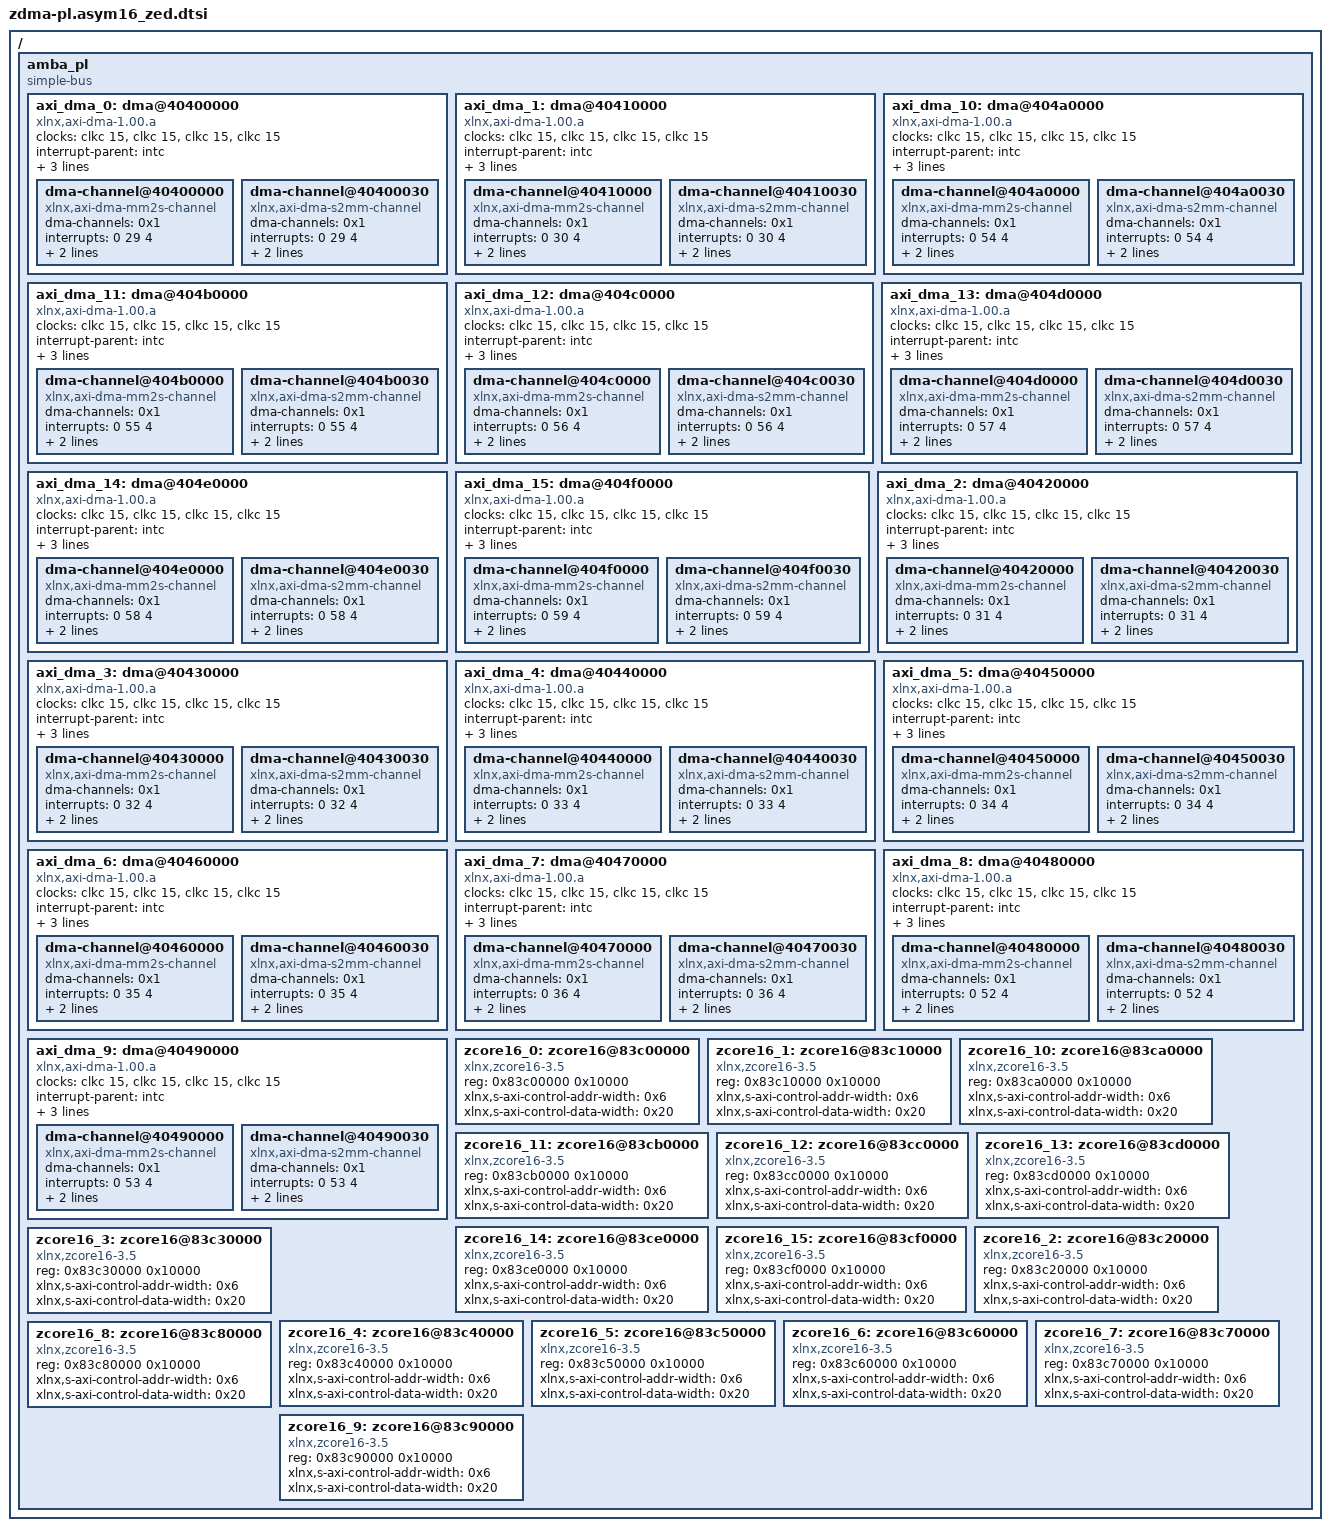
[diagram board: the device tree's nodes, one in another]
/ {
	amba_pl: amba_pl {
		#address-cells = <1>;
		#size-cells = <1>;
		compatible = "simple-bus";
		ranges ;
		axi_dma_0: dma@40400000 {
			#dma-cells = <1>;
			clock-names = "s_axi_lite_aclk", "m_axi_sg_aclk", "m_axi_mm2s_aclk", "m_axi_s2mm_aclk";
			clocks = <&clkc 15>, <&clkc 15>, <&clkc 15>, <&clkc 15>;
			compatible = "xlnx,axi-dma-1.00.a";
			interrupt-parent = <&intc>;
			interrupts = <0 29 4>;
			reg = <0x40400000 0x10000>;
			xlnx,addrwidth = <0x20>;
			dma-channel@40400000 {
				compatible = "xlnx,axi-dma-mm2s-channel";
				dma-channels = <0x1>;
				interrupts = <0 29 4>;
				xlnx,datawidth = <0x10>;
				xlnx,device-id = <0x0>;
			};
			dma-channel@40400030 {
				compatible = "xlnx,axi-dma-s2mm-channel";
				dma-channels = <0x1>;
				interrupts = <0 29 4>;
				xlnx,datawidth = <0x10>;
				xlnx,device-id = <0x0>;
			};
		};
		axi_dma_1: dma@40410000 {
			#dma-cells = <1>;
			clock-names = "s_axi_lite_aclk", "m_axi_sg_aclk", "m_axi_mm2s_aclk", "m_axi_s2mm_aclk";
			clocks = <&clkc 15>, <&clkc 15>, <&clkc 15>, <&clkc 15>;
			compatible = "xlnx,axi-dma-1.00.a";
			interrupt-parent = <&intc>;
			interrupts = <0 30 4>;
			reg = <0x40410000 0x10000>;
			xlnx,addrwidth = <0x20>;
			dma-channel@40410000 {
				compatible = "xlnx,axi-dma-mm2s-channel";
				dma-channels = <0x1>;
				interrupts = <0 30 4>;
				xlnx,datawidth = <0x10>;
				xlnx,device-id = <0x1>;
			};
			dma-channel@40410030 {
				compatible = "xlnx,axi-dma-s2mm-channel";
				dma-channels = <0x1>;
				interrupts = <0 30 4>;
				xlnx,datawidth = <0x10>;
				xlnx,device-id = <0x1>;
			};
		};
		axi_dma_10: dma@404a0000 {
			#dma-cells = <1>;
			clock-names = "s_axi_lite_aclk", "m_axi_sg_aclk", "m_axi_mm2s_aclk", "m_axi_s2mm_aclk";
			clocks = <&clkc 15>, <&clkc 15>, <&clkc 15>, <&clkc 15>;
			compatible = "xlnx,axi-dma-1.00.a";
			interrupt-parent = <&intc>;
			interrupts = <0 54 4>;
			reg = <0x404a0000 0x10000>;
			xlnx,addrwidth = <0x20>;
			dma-channel@404a0000 {
				compatible = "xlnx,axi-dma-mm2s-channel";
				dma-channels = <0x1>;
				interrupts = <0 54 4>;
				xlnx,datawidth = <0x10>;
				xlnx,device-id = <0x2>;
			};
			dma-channel@404a0030 {
				compatible = "xlnx,axi-dma-s2mm-channel";
				dma-channels = <0x1>;
				interrupts = <0 54 4>;
				xlnx,datawidth = <0x10>;
				xlnx,device-id = <0x2>;
			};
		};
		axi_dma_11: dma@404b0000 {
			#dma-cells = <1>;
			clock-names = "s_axi_lite_aclk", "m_axi_sg_aclk", "m_axi_mm2s_aclk", "m_axi_s2mm_aclk";
			clocks = <&clkc 15>, <&clkc 15>, <&clkc 15>, <&clkc 15>;
			compatible = "xlnx,axi-dma-1.00.a";
			interrupt-parent = <&intc>;
			interrupts = <0 55 4>;
			reg = <0x404b0000 0x10000>;
			xlnx,addrwidth = <0x20>;
			dma-channel@404b0000 {
				compatible = "xlnx,axi-dma-mm2s-channel";
				dma-channels = <0x1>;
				interrupts = <0 55 4>;
				xlnx,datawidth = <0x10>;
				xlnx,device-id = <0x3>;
			};
			dma-channel@404b0030 {
				compatible = "xlnx,axi-dma-s2mm-channel";
				dma-channels = <0x1>;
				interrupts = <0 55 4>;
				xlnx,datawidth = <0x10>;
				xlnx,device-id = <0x3>;
			};
		};
		axi_dma_12: dma@404c0000 {
			#dma-cells = <1>;
			clock-names = "s_axi_lite_aclk", "m_axi_sg_aclk", "m_axi_mm2s_aclk", "m_axi_s2mm_aclk";
			clocks = <&clkc 15>, <&clkc 15>, <&clkc 15>, <&clkc 15>;
			compatible = "xlnx,axi-dma-1.00.a";
			interrupt-parent = <&intc>;
			interrupts = <0 56 4>;
			reg = <0x404c0000 0x10000>;
			xlnx,addrwidth = <0x20>;
			dma-channel@404c0000 {
				compatible = "xlnx,axi-dma-mm2s-channel";
				dma-channels = <0x1>;
				interrupts = <0 56 4>;
				xlnx,datawidth = <0x10>;
				xlnx,device-id = <0x4>;
			};
			dma-channel@404c0030 {
				compatible = "xlnx,axi-dma-s2mm-channel";
				dma-channels = <0x1>;
				interrupts = <0 56 4>;
				xlnx,datawidth = <0x10>;
				xlnx,device-id = <0x4>;
			};
		};
		axi_dma_13: dma@404d0000 {
			#dma-cells = <1>;
			clock-names = "s_axi_lite_aclk", "m_axi_sg_aclk", "m_axi_mm2s_aclk", "m_axi_s2mm_aclk";
			clocks = <&clkc 15>, <&clkc 15>, <&clkc 15>, <&clkc 15>;
			compatible = "xlnx,axi-dma-1.00.a";
			interrupt-parent = <&intc>;
			interrupts = <0 57 4>;
			reg = <0x404d0000 0x10000>;
			xlnx,addrwidth = <0x20>;
			dma-channel@404d0000 {
				compatible = "xlnx,axi-dma-mm2s-channel";
				dma-channels = <0x1>;
				interrupts = <0 57 4>;
				xlnx,datawidth = <0x10>;
				xlnx,device-id = <0x5>;
			};
			dma-channel@404d0030 {
				compatible = "xlnx,axi-dma-s2mm-channel";
				dma-channels = <0x1>;
				interrupts = <0 57 4>;
				xlnx,datawidth = <0x10>;
				xlnx,device-id = <0x5>;
			};
		};
		axi_dma_14: dma@404e0000 {
			#dma-cells = <1>;
			clock-names = "s_axi_lite_aclk", "m_axi_sg_aclk", "m_axi_mm2s_aclk", "m_axi_s2mm_aclk";
			clocks = <&clkc 15>, <&clkc 15>, <&clkc 15>, <&clkc 15>;
			compatible = "xlnx,axi-dma-1.00.a";
			interrupt-parent = <&intc>;
			interrupts = <0 58 4>;
			reg = <0x404e0000 0x10000>;
			xlnx,addrwidth = <0x20>;
			dma-channel@404e0000 {
				compatible = "xlnx,axi-dma-mm2s-channel";
				dma-channels = <0x1>;
				interrupts = <0 58 4>;
				xlnx,datawidth = <0x10>;
				xlnx,device-id = <0x6>;
			};
			dma-channel@404e0030 {
				compatible = "xlnx,axi-dma-s2mm-channel";
				dma-channels = <0x1>;
				interrupts = <0 58 4>;
				xlnx,datawidth = <0x10>;
				xlnx,device-id = <0x6>;
			};
		};
		axi_dma_15: dma@404f0000 {
			#dma-cells = <1>;
			clock-names = "s_axi_lite_aclk", "m_axi_sg_aclk", "m_axi_mm2s_aclk", "m_axi_s2mm_aclk";
			clocks = <&clkc 15>, <&clkc 15>, <&clkc 15>, <&clkc 15>;
			compatible = "xlnx,axi-dma-1.00.a";
			interrupt-parent = <&intc>;
			interrupts = <0 59 4>;
			reg = <0x404f0000 0x10000>;
			xlnx,addrwidth = <0x20>;
			dma-channel@404f0000 {
				compatible = "xlnx,axi-dma-mm2s-channel";
				dma-channels = <0x1>;
				interrupts = <0 59 4>;
				xlnx,datawidth = <0x10>;
				xlnx,device-id = <0x7>;
			};
			dma-channel@404f0030 {
				compatible = "xlnx,axi-dma-s2mm-channel";
				dma-channels = <0x1>;
				interrupts = <0 59 4>;
				xlnx,datawidth = <0x10>;
				xlnx,device-id = <0x7>;
			};
		};
		axi_dma_2: dma@40420000 {
			#dma-cells = <1>;
			clock-names = "s_axi_lite_aclk", "m_axi_sg_aclk", "m_axi_mm2s_aclk", "m_axi_s2mm_aclk";
			clocks = <&clkc 15>, <&clkc 15>, <&clkc 15>, <&clkc 15>;
			compatible = "xlnx,axi-dma-1.00.a";
			interrupt-parent = <&intc>;
			interrupts = <0 31 4>;
			reg = <0x40420000 0x10000>;
			xlnx,addrwidth = <0x20>;
			dma-channel@40420000 {
				compatible = "xlnx,axi-dma-mm2s-channel";
				dma-channels = <0x1>;
				interrupts = <0 31 4>;
				xlnx,datawidth = <0x10>;
				xlnx,device-id = <0x8>;
			};
			dma-channel@40420030 {
				compatible = "xlnx,axi-dma-s2mm-channel";
				dma-channels = <0x1>;
				interrupts = <0 31 4>;
				xlnx,datawidth = <0x10>;
				xlnx,device-id = <0x8>;
			};
		};
		axi_dma_3: dma@40430000 {
			#dma-cells = <1>;
			clock-names = "s_axi_lite_aclk", "m_axi_sg_aclk", "m_axi_mm2s_aclk", "m_axi_s2mm_aclk";
			clocks = <&clkc 15>, <&clkc 15>, <&clkc 15>, <&clkc 15>;
			compatible = "xlnx,axi-dma-1.00.a";
			interrupt-parent = <&intc>;
			interrupts = <0 32 4>;
			reg = <0x40430000 0x10000>;
			xlnx,addrwidth = <0x20>;
			dma-channel@40430000 {
				compatible = "xlnx,axi-dma-mm2s-channel";
				dma-channels = <0x1>;
				interrupts = <0 32 4>;
				xlnx,datawidth = <0x10>;
				xlnx,device-id = <0x9>;
			};
			dma-channel@40430030 {
				compatible = "xlnx,axi-dma-s2mm-channel";
				dma-channels = <0x1>;
				interrupts = <0 32 4>;
				xlnx,datawidth = <0x10>;
				xlnx,device-id = <0x9>;
			};
		};
		axi_dma_4: dma@40440000 {
			#dma-cells = <1>;
			clock-names = "s_axi_lite_aclk", "m_axi_sg_aclk", "m_axi_mm2s_aclk", "m_axi_s2mm_aclk";
			clocks = <&clkc 15>, <&clkc 15>, <&clkc 15>, <&clkc 15>;
			compatible = "xlnx,axi-dma-1.00.a";
			interrupt-parent = <&intc>;
			interrupts = <0 33 4>;
			reg = <0x40440000 0x10000>;
			xlnx,addrwidth = <0x20>;
			dma-channel@40440000 {
				compatible = "xlnx,axi-dma-mm2s-channel";
				dma-channels = <0x1>;
				interrupts = <0 33 4>;
				xlnx,datawidth = <0x10>;
				xlnx,device-id = <0xa>;
			};
			dma-channel@40440030 {
				compatible = "xlnx,axi-dma-s2mm-channel";
				dma-channels = <0x1>;
				interrupts = <0 33 4>;
				xlnx,datawidth = <0x10>;
				xlnx,device-id = <0xa>;
			};
		};
		axi_dma_5: dma@40450000 {
			#dma-cells = <1>;
			clock-names = "s_axi_lite_aclk", "m_axi_sg_aclk", "m_axi_mm2s_aclk", "m_axi_s2mm_aclk";
			clocks = <&clkc 15>, <&clkc 15>, <&clkc 15>, <&clkc 15>;
			compatible = "xlnx,axi-dma-1.00.a";
			interrupt-parent = <&intc>;
			interrupts = <0 34 4>;
			reg = <0x40450000 0x10000>;
			xlnx,addrwidth = <0x20>;
			dma-channel@40450000 {
				compatible = "xlnx,axi-dma-mm2s-channel";
				dma-channels = <0x1>;
				interrupts = <0 34 4>;
				xlnx,datawidth = <0x10>;
				xlnx,device-id = <0xb>;
			};
			dma-channel@40450030 {
				compatible = "xlnx,axi-dma-s2mm-channel";
				dma-channels = <0x1>;
				interrupts = <0 34 4>;
				xlnx,datawidth = <0x10>;
				xlnx,device-id = <0xb>;
			};
		};
		axi_dma_6: dma@40460000 {
			#dma-cells = <1>;
			clock-names = "s_axi_lite_aclk", "m_axi_sg_aclk", "m_axi_mm2s_aclk", "m_axi_s2mm_aclk";
			clocks = <&clkc 15>, <&clkc 15>, <&clkc 15>, <&clkc 15>;
			compatible = "xlnx,axi-dma-1.00.a";
			interrupt-parent = <&intc>;
			interrupts = <0 35 4>;
			reg = <0x40460000 0x10000>;
			xlnx,addrwidth = <0x20>;
			dma-channel@40460000 {
				compatible = "xlnx,axi-dma-mm2s-channel";
				dma-channels = <0x1>;
				interrupts = <0 35 4>;
				xlnx,datawidth = <0x10>;
				xlnx,device-id = <0xc>;
			};
			dma-channel@40460030 {
				compatible = "xlnx,axi-dma-s2mm-channel";
				dma-channels = <0x1>;
				interrupts = <0 35 4>;
				xlnx,datawidth = <0x10>;
				xlnx,device-id = <0xc>;
			};
		};
		axi_dma_7: dma@40470000 {
			#dma-cells = <1>;
			clock-names = "s_axi_lite_aclk", "m_axi_sg_aclk", "m_axi_mm2s_aclk", "m_axi_s2mm_aclk";
			clocks = <&clkc 15>, <&clkc 15>, <&clkc 15>, <&clkc 15>;
			compatible = "xlnx,axi-dma-1.00.a";
			interrupt-parent = <&intc>;
			interrupts = <0 36 4>;
			reg = <0x40470000 0x10000>;
			xlnx,addrwidth = <0x20>;
			dma-channel@40470000 {
				compatible = "xlnx,axi-dma-mm2s-channel";
				dma-channels = <0x1>;
				interrupts = <0 36 4>;
				xlnx,datawidth = <0x10>;
				xlnx,device-id = <0xd>;
			};
			dma-channel@40470030 {
				compatible = "xlnx,axi-dma-s2mm-channel";
				dma-channels = <0x1>;
				interrupts = <0 36 4>;
				xlnx,datawidth = <0x10>;
				xlnx,device-id = <0xd>;
			};
		};
		axi_dma_8: dma@40480000 {
			#dma-cells = <1>;
			clock-names = "s_axi_lite_aclk", "m_axi_sg_aclk", "m_axi_mm2s_aclk", "m_axi_s2mm_aclk";
			clocks = <&clkc 15>, <&clkc 15>, <&clkc 15>, <&clkc 15>;
			compatible = "xlnx,axi-dma-1.00.a";
			interrupt-parent = <&intc>;
			interrupts = <0 52 4>;
			reg = <0x40480000 0x10000>;
			xlnx,addrwidth = <0x20>;
			dma-channel@40480000 {
				compatible = "xlnx,axi-dma-mm2s-channel";
				dma-channels = <0x1>;
				interrupts = <0 52 4>;
				xlnx,datawidth = <0x10>;
				xlnx,device-id = <0xe>;
			};
			dma-channel@40480030 {
				compatible = "xlnx,axi-dma-s2mm-channel";
				dma-channels = <0x1>;
				interrupts = <0 52 4>;
				xlnx,datawidth = <0x10>;
				xlnx,device-id = <0xe>;
			};
		};
		axi_dma_9: dma@40490000 {
			#dma-cells = <1>;
			clock-names = "s_axi_lite_aclk", "m_axi_sg_aclk", "m_axi_mm2s_aclk", "m_axi_s2mm_aclk";
			clocks = <&clkc 15>, <&clkc 15>, <&clkc 15>, <&clkc 15>;
			compatible = "xlnx,axi-dma-1.00.a";
			interrupt-parent = <&intc>;
			interrupts = <0 53 4>;
			reg = <0x40490000 0x10000>;
			xlnx,addrwidth = <0x20>;
			dma-channel@40490000 {
				compatible = "xlnx,axi-dma-mm2s-channel";
				dma-channels = <0x1>;
				interrupts = <0 53 4>;
				xlnx,datawidth = <0x10>;
				xlnx,device-id = <0xf>;
			};
			dma-channel@40490030 {
				compatible = "xlnx,axi-dma-s2mm-channel";
				dma-channels = <0x1>;
				interrupts = <0 53 4>;
				xlnx,datawidth = <0x10>;
				xlnx,device-id = <0xf>;
			};
		};
		zcore16_0: zcore16@83c00000 {
			compatible = "xlnx,zcore16-3.5";
			reg = <0x83c00000 0x10000>;
			xlnx,s-axi-control-addr-width = <0x6>;
			xlnx,s-axi-control-data-width = <0x20>;
		};
		zcore16_1: zcore16@83c10000 {
			compatible = "xlnx,zcore16-3.5";
			reg = <0x83c10000 0x10000>;
			xlnx,s-axi-control-addr-width = <0x6>;
			xlnx,s-axi-control-data-width = <0x20>;
		};
		zcore16_10: zcore16@83ca0000 {
			compatible = "xlnx,zcore16-3.5";
			reg = <0x83ca0000 0x10000>;
			xlnx,s-axi-control-addr-width = <0x6>;
			xlnx,s-axi-control-data-width = <0x20>;
		};
		zcore16_11: zcore16@83cb0000 {
			compatible = "xlnx,zcore16-3.5";
			reg = <0x83cb0000 0x10000>;
			xlnx,s-axi-control-addr-width = <0x6>;
			xlnx,s-axi-control-data-width = <0x20>;
		};
		zcore16_12: zcore16@83cc0000 {
			compatible = "xlnx,zcore16-3.5";
			reg = <0x83cc0000 0x10000>;
			xlnx,s-axi-control-addr-width = <0x6>;
			xlnx,s-axi-control-data-width = <0x20>;
		};
		zcore16_13: zcore16@83cd0000 {
			compatible = "xlnx,zcore16-3.5";
			reg = <0x83cd0000 0x10000>;
			xlnx,s-axi-control-addr-width = <0x6>;
			xlnx,s-axi-control-data-width = <0x20>;
		};
		zcore16_14: zcore16@83ce0000 {
			compatible = "xlnx,zcore16-3.5";
			reg = <0x83ce0000 0x10000>;
			xlnx,s-axi-control-addr-width = <0x6>;
			xlnx,s-axi-control-data-width = <0x20>;
		};
		zcore16_15: zcore16@83cf0000 {
			compatible = "xlnx,zcore16-3.5";
			reg = <0x83cf0000 0x10000>;
			xlnx,s-axi-control-addr-width = <0x6>;
			xlnx,s-axi-control-data-width = <0x20>;
		};
		zcore16_2: zcore16@83c20000 {
			compatible = "xlnx,zcore16-3.5";
			reg = <0x83c20000 0x10000>;
			xlnx,s-axi-control-addr-width = <0x6>;
			xlnx,s-axi-control-data-width = <0x20>;
		};
		zcore16_3: zcore16@83c30000 {
			compatible = "xlnx,zcore16-3.5";
			reg = <0x83c30000 0x10000>;
			xlnx,s-axi-control-addr-width = <0x6>;
			xlnx,s-axi-control-data-width = <0x20>;
		};
		zcore16_4: zcore16@83c40000 {
			compatible = "xlnx,zcore16-3.5";
			reg = <0x83c40000 0x10000>;
			xlnx,s-axi-control-addr-width = <0x6>;
			xlnx,s-axi-control-data-width = <0x20>;
		};
		zcore16_5: zcore16@83c50000 {
			compatible = "xlnx,zcore16-3.5";
			reg = <0x83c50000 0x10000>;
			xlnx,s-axi-control-addr-width = <0x6>;
			xlnx,s-axi-control-data-width = <0x20>;
		};
		zcore16_6: zcore16@83c60000 {
			compatible = "xlnx,zcore16-3.5";
			reg = <0x83c60000 0x10000>;
			xlnx,s-axi-control-addr-width = <0x6>;
			xlnx,s-axi-control-data-width = <0x20>;
		};
		zcore16_7: zcore16@83c70000 {
			compatible = "xlnx,zcore16-3.5";
			reg = <0x83c70000 0x10000>;
			xlnx,s-axi-control-addr-width = <0x6>;
			xlnx,s-axi-control-data-width = <0x20>;
		};
		zcore16_8: zcore16@83c80000 {
			compatible = "xlnx,zcore16-3.5";
			reg = <0x83c80000 0x10000>;
			xlnx,s-axi-control-addr-width = <0x6>;
			xlnx,s-axi-control-data-width = <0x20>;
		};
		zcore16_9: zcore16@83c90000 {
			compatible = "xlnx,zcore16-3.5";
			reg = <0x83c90000 0x10000>;
			xlnx,s-axi-control-addr-width = <0x6>;
			xlnx,s-axi-control-data-width = <0x20>;
		};
	};
};
